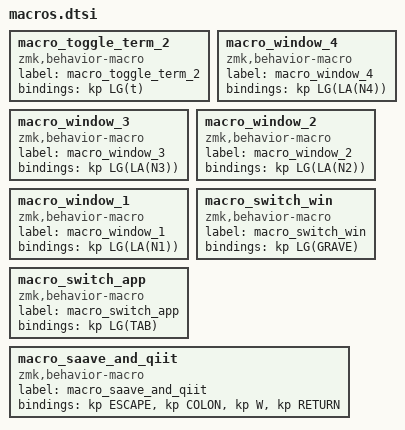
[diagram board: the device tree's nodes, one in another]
macro_toggle_term_2: macro_toggle_term_2{
compatible = "zmk,behavior-macro";
label = "macro_toggle_term_2";
#binding-cells = <0>;
bindings = <&kp LG(t)>;
};
macro_window_4: macro_window_4{
compatible = "zmk,behavior-macro";
label = "macro_window_4";
#binding-cells = <0>;
bindings = <&kp LG(LA(N4))>;
};
macro_window_3: macro_window_3{
compatible = "zmk,behavior-macro";
label = "macro_window_3";
#binding-cells = <0>;
bindings = <&kp LG(LA(N3))>;
};
macro_window_2: macro_window_2{
compatible = "zmk,behavior-macro";
label = "macro_window_2";
#binding-cells = <0>;
bindings = <&kp LG(LA(N2))>;
};
macro_window_1: macro_window_1{
compatible = "zmk,behavior-macro";
label = "macro_window_1";
#binding-cells = <0>;
bindings = <&kp LG(LA(N1))>;
};
macro_switch_win: macro_switch_win{
compatible = "zmk,behavior-macro";
label = "macro_switch_win";
#binding-cells = <0>;
bindings = <&kp LG(GRAVE)>;
};
macro_switch_app: macro_switch_app{
compatible = "zmk,behavior-macro";
label = "macro_switch_app";
#binding-cells = <0>;
bindings = <&kp LG(TAB)>;
};
macro_saave_and_qiit: macro_saave_and_qiit{
compatible = "zmk,behavior-macro";
label = "macro_saave_and_qiit";
#binding-cells = <0>;
bindings = <&kp ESCAPE>, <&kp COLON>, <&kp W>, <&kp RETURN>;
};
